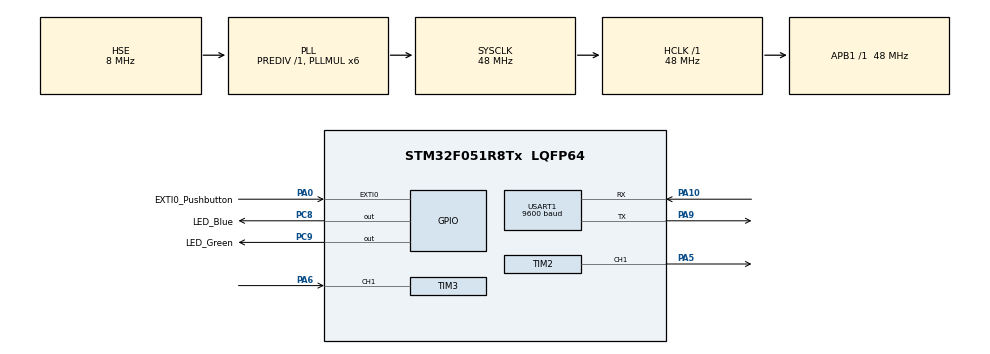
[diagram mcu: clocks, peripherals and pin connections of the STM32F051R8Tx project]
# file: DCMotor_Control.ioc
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Dma.Request0=USART1_TX
Dma.Request1=TIM2_CH1
Dma.TIM2_CH1.1.Direction=DMA_PERIPH_TO_MEMORY
Dma.TIM2_CH1.1.Instance=DMA1_Channel5
Dma.TIM2_CH1.1.MemDataAlignment=DMA_MDATAALIGN_WORD
Dma.TIM2_CH1.1.MemInc=DMA_MINC_ENABLE
Dma.TIM2_CH1.1.Mode=DMA_NORMAL
Dma.TIM2_CH1.1.PeriphDataAlignment=DMA_PDATAALIGN_WORD
Dma.TIM2_CH1.1.PeriphInc=DMA_PINC_DISABLE
Dma.TIM2_CH1.1.Priority=DMA_PRIORITY_LOW
Dma.USART1_TX.0.Direction=DMA_MEMORY_TO_PERIPH
Dma.USART1_TX.0.Instance=DMA1_Channel2
Dma.USART1_TX.0.MemDataAlignment=DMA_MDATAALIGN_BYTE
Dma.USART1_TX.0.MemInc=DMA_MINC_ENABLE
Dma.USART1_TX.0.Mode=DMA_NORMAL
Dma.USART1_TX.0.PeriphDataAlignment=DMA_PDATAALIGN_BYTE
Dma.USART1_TX.0.PeriphInc=DMA_PINC_DISABLE
Dma.USART1_TX.0.Priority=DMA_PRIORITY_LOW
Mcu.Family=STM32F0
Mcu.Name=STM32F051R8Tx
Mcu.Package=LQFP64
NVIC.DMA1_Channel2_3_IRQn=true\:0\:0\:false\:false\:true\:false\:true\:true
NVIC.DMA1_Channel4_5_IRQn=true\:0\:0\:false\:false\:true\:false\:true\:true
NVIC.EXTI0_1_IRQn=true\:0\:0\:false\:false\:true\:true\:true\:true
NVIC.TIM3_IRQn=true\:0\:0\:false\:false\:true\:true\:true\:true
NVIC.TIM6_DAC_IRQn=true\:0\:0\:false\:false\:true\:true\:true\:true
PA0.GPIO_Label=EXTI0_Pushbutton
PA0.Signal=GPXTI0
PA10.Mode=Asynchronous
PA10.Signal=USART1_RX
PA13.GPIO_Label=SWDIO
PA13.Mode=Serial_Wire
PA13.Signal=SYS_SWDIO
PA14.GPIO_Label=SWCLK
PA14.Mode=Serial_Wire
PA14.Signal=SYS_SWCLK
PA5.Signal=S_TIM2_CH1_ETR
PA6.Signal=S_TIM3_CH1
PA9.Mode=Asynchronous
PA9.Signal=USART1_TX
PC8.GPIO_Label=LED_Blue
PC8.Signal=GPIO_Output
PC9.GPIO_Label=LED_Green
PC9.Signal=GPIO_Output
PF0-OSC_IN.Mode=HSE-External-Oscillator
PF0-OSC_IN.Signal=RCC_OSC_IN
PF1-OSC_OUT.Mode=HSE-External-Oscillator
PF1-OSC_OUT.Signal=RCC_OSC_OUT
ProjectManager.HeapSize=0x200
ProjectManager.StackSize=0x400
ProjectManager.TargetToolchain=STM32CubeIDE
RCC.AHBFreq_Value=48000000
RCC.APB1Freq_Value=48000000
RCC.APB1TimFreq_Value=48000000
RCC.HCLKFreq_Value=48000000
RCC.PLLMUL=RCC_PLL_MUL6
RCC.PLLSourceVirtual=RCC_PLLSOURCE_HSE
RCC.SYSCLKFreq_VALUE=48000000
RCC.SYSCLKSource=RCC_SYSCLKSOURCE_PLLCLK
SH.S_TIM2_CH1_ETR.0=TIM2_CH1,PWM Generation1 CH1
SH.S_TIM3_CH1.0=TIM3_CH1,Input_Capture1_from_TI1
TIM2.Channel-PWM\ Generation1\ CH1=TIM_CHANNEL_1
TIM2.Period=100-1
TIM2.Prescaler=48-1
TIM3.AutoReloadPreload=TIM_AUTORELOAD_PRELOAD_DISABLE
TIM3.Channel-Input_Capture1_from_TI1=TIM_CHANNEL_1
TIM3.Period=0xFFFF
TIM3.Prescaler=48-1
TIM6.Period=100-1
TIM6.Prescaler=48000-1
USART1.BaudRate=9600
USART1.VirtualMode-Asynchronous=VM_ASYNC
VP_TIM2_VS_ClockSourceINT.Mode=Internal
VP_TIM3_VS_ClockSourceINT.Mode=Internal
VP_TIM6_VS_ClockSourceINT.Mode=Enable_Timer
board=STM32F0DISCOVERY

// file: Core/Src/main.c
/* USER CODE BEGIN Header */
/**
  ******************************************************************************
  * @file           : main.c
  * @brief          : Main program body
  ******************************************************************************
  * @attention
  *
  * Copyright (c) 2025 STMicroelectronics.
  * All rights reserved.
  *
  * This software is licensed under terms that can be found in the LICENSE file
  * in the root directory of this software component.
  * If no LICENSE file comes with this software, it is provided AS-IS.
  *
  ******************************************************************************
  */
/* USER CODE END Header */
#include "main.h"

TIM_HandleTypeDef htim2;
TIM_HandleTypeDef htim3;
TIM_HandleTypeDef htim6;
DMA_HandleTypeDef hdma_tim2_ch1;

UART_HandleTypeDef huart1;
DMA_HandleTypeDef hdma_usart1_tx;

void SystemClock_Config(void);
static void MX_GPIO_Init(void);
static void MX_DMA_Init(void);
static void MX_USART1_UART_Init(void);
static void MX_TIM6_Init(void);
static void MX_TIM2_Init(void);
static void MX_TIM3_Init(void);

int main(void)
{

  /* MCU Configuration--------------------------------------------------------*/

  /* Reset of all peripherals, Initializes the Flash interface and the Systick. */
  HAL_Init();

  /* Configure the system clock */
  SystemClock_Config();

  /* Initialize all configured peripherals */
  MX_GPIO_Init();
  MX_DMA_Init();
  MX_USART1_UART_Init();
  MX_TIM6_Init();
  MX_TIM2_Init();
  MX_TIM3_Init();
  /* USER CODE BEGIN 2 */
  app_entry();
  /* USER CODE END 2 */

  /* Infinite loop */
  while (1)
  {

  }
}

void SystemClock_Config(void)
{
  RCC_OscInitTypeDef RCC_OscInitStruct = {0};
  RCC_ClkInitTypeDef RCC_ClkInitStruct = {0};
  RCC_PeriphCLKInitTypeDef PeriphClkInit = {0};

  /** Initializes the RCC Oscillators according to the specified parameters
  * in the RCC_OscInitTypeDef structure.
  */
  RCC_OscInitStruct.OscillatorType = RCC_OSCILLATORTYPE_HSE;
  RCC_OscInitStruct.HSEState = RCC_HSE_ON;
  RCC_OscInitStruct.PLL.PLLState = RCC_PLL_ON;
  RCC_OscInitStruct.PLL.PLLSource = RCC_PLLSOURCE_HSE;
  RCC_OscInitStruct.PLL.PLLMUL = RCC_PLL_MUL6;
  RCC_OscInitStruct.PLL.PREDIV = RCC_PREDIV_DIV1;
  if (HAL_RCC_OscConfig(&RCC_OscInitStruct) != HAL_OK)
  {
    Error_Handler();
  }

  /** Initializes the CPU, AHB and APB buses clocks
  */
  RCC_ClkInitStruct.ClockType = RCC_CLOCKTYPE_HCLK|RCC_CLOCKTYPE_SYSCLK
                              |RCC_CLOCKTYPE_PCLK1;
  RCC_ClkInitStruct.SYSCLKSource = RCC_SYSCLKSOURCE_PLLCLK;
  RCC_ClkInitStruct.AHBCLKDivider = RCC_SYSCLK_DIV1;
  RCC_ClkInitStruct.APB1CLKDivider = RCC_HCLK_DIV1;

  if (HAL_RCC_ClockConfig(&RCC_ClkInitStruct, FLASH_LATENCY_1) != HAL_OK)
  {
    Error_Handler();
  }
  PeriphClkInit.PeriphClockSelection = RCC_PERIPHCLK_USART1;
  PeriphClkInit.Usart1ClockSelection = RCC_USART1CLKSOURCE_PCLK1;
  if (HAL_RCCEx_PeriphCLKConfig(&PeriphClkInit) != HAL_OK)
  {
    Error_Handler();
  }
}

static void MX_TIM2_Init(void)
{

  TIM_ClockConfigTypeDef sClockSourceConfig = {0};
  TIM_MasterConfigTypeDef sMasterConfig = {0};
  TIM_OC_InitTypeDef sConfigOC = {0};

  htim2.Instance = TIM2;
  htim2.Init.Prescaler = 48-1;
  htim2.Init.CounterMode = TIM_COUNTERMODE_UP;
  htim2.Init.Period = 100-1;
  htim2.Init.ClockDivision = TIM_CLOCKDIVISION_DIV1;
  htim2.Init.AutoReloadPreload = TIM_AUTORELOAD_PRELOAD_DISABLE;
  if (HAL_TIM_Base_Init(&htim2) != HAL_OK)
  {
    Error_Handler();
  }
  sClockSourceConfig.ClockSource = TIM_CLOCKSOURCE_INTERNAL;
  if (HAL_TIM_ConfigClockSource(&htim2, &sClockSourceConfig) != HAL_OK)
  {
    Error_Handler();
  }
  if (HAL_TIM_PWM_Init(&htim2) != HAL_OK)
  {
    Error_Handler();
  }
  sMasterConfig.MasterOutputTrigger = TIM_TRGO_RESET;
  sMasterConfig.MasterSlaveMode = TIM_MASTERSLAVEMODE_DISABLE;
  if (HAL_TIMEx_MasterConfigSynchronization(&htim2, &sMasterConfig) != HAL_OK)
  {
    Error_Handler();
  }
  sConfigOC.OCMode = TIM_OCMODE_PWM1;
  sConfigOC.Pulse = 0;
  sConfigOC.OCPolarity = TIM_OCPOLARITY_HIGH;
  sConfigOC.OCFastMode = TIM_OCFAST_DISABLE;
  if (HAL_TIM_PWM_ConfigChannel(&htim2, &sConfigOC, TIM_CHANNEL_1) != HAL_OK)
  {
    Error_Handler();
  }
  HAL_TIM_MspPostInit(&htim2);

}

static void MX_TIM3_Init(void)
{

  TIM_ClockConfigTypeDef sClockSourceConfig = {0};
  TIM_MasterConfigTypeDef sMasterConfig = {0};
  TIM_IC_InitTypeDef sConfigIC = {0};

  htim3.Instance = TIM3;
  htim3.Init.Prescaler = 48-1;
  htim3.Init.CounterMode = TIM_COUNTERMODE_UP;
  htim3.Init.Period = 0xFFFF;
  htim3.Init.ClockDivision = TIM_CLOCKDIVISION_DIV1;
  htim3.Init.AutoReloadPreload = TIM_AUTORELOAD_PRELOAD_DISABLE;
  if (HAL_TIM_Base_Init(&htim3) != HAL_OK)
  {
    Error_Handler();
  }
  sClockSourceConfig.ClockSource = TIM_CLOCKSOURCE_INTERNAL;
  if (HAL_TIM_ConfigClockSource(&htim3, &sClockSourceConfig) != HAL_OK)
  {
    Error_Handler();
  }
  if (HAL_TIM_IC_Init(&htim3) != HAL_OK)
  {
    Error_Handler();
  }
  sMasterConfig.MasterOutputTrigger = TIM_TRGO_RESET;
  sMasterConfig.MasterSlaveMode = TIM_MASTERSLAVEMODE_DISABLE;
  if (HAL_TIMEx_MasterConfigSynchronization(&htim3, &sMasterConfig) != HAL_OK)
  {
    Error_Handler();
  }
  sConfigIC.ICPolarity = TIM_INPUTCHANNELPOLARITY_RISING;
  sConfigIC.ICSelection = TIM_ICSELECTION_DIRECTTI;
  sConfigIC.ICPrescaler = TIM_ICPSC_DIV1;
  sConfigIC.ICFilter = 0;
  if (HAL_TIM_IC_ConfigChannel(&htim3, &sConfigIC, TIM_CHANNEL_1) != HAL_OK)
  {
    Error_Handler();
  }

}

static void MX_TIM6_Init(void)
{

  TIM_MasterConfigTypeDef sMasterConfig = {0};

  htim6.Instance = TIM6;
  htim6.Init.Prescaler = 48000-1;
  htim6.Init.CounterMode = TIM_COUNTERMODE_UP;
  htim6.Init.Period = 100-1;
  htim6.Init.AutoReloadPreload = TIM_AUTORELOAD_PRELOAD_DISABLE;
  if (HAL_TIM_Base_Init(&htim6) != HAL_OK)
  {
    Error_Handler();
  }
  sMasterConfig.MasterOutputTrigger = TIM_TRGO_RESET;
  sMasterConfig.MasterSlaveMode = TIM_MASTERSLAVEMODE_DISABLE;
  if (HAL_TIMEx_MasterConfigSynchronization(&htim6, &sMasterConfig) != HAL_OK)
  {
    Error_Handler();
  }

}

static void MX_USART1_UART_Init(void)
{

  huart1.Instance = USART1;
  huart1.Init.BaudRate = 9600;
  huart1.Init.WordLength = UART_WORDLENGTH_8B;
  huart1.Init.StopBits = UART_STOPBITS_1;
  huart1.Init.Parity = UART_PARITY_NONE;
  huart1.Init.Mode = UART_MODE_TX_RX;
  huart1.Init.HwFlowCtl = UART_HWCONTROL_NONE;
  huart1.Init.OverSampling = UART_OVERSAMPLING_16;
  huart1.Init.OneBitSampling = UART_ONE_BIT_SAMPLE_DISABLE;
  huart1.AdvancedInit.AdvFeatureInit = UART_ADVFEATURE_NO_INIT;
  if (HAL_UART_Init(&huart1) != HAL_OK)
  {
    Error_Handler();
  }

}

static void MX_DMA_Init(void)
{

  /* DMA controller clock enable */
  __HAL_RCC_DMA1_CLK_ENABLE();

  /* DMA interrupt init */
  /* DMA1_Channel2_3_IRQn interrupt configuration */
  HAL_NVIC_SetPriority(DMA1_Channel2_3_IRQn, 0, 0);
  HAL_NVIC_EnableIRQ(DMA1_Channel2_3_IRQn);
  /* DMA1_Channel4_5_IRQn interrupt configuration */
  HAL_NVIC_SetPriority(DMA1_Channel4_5_IRQn, 0, 0);
  HAL_NVIC_EnableIRQ(DMA1_Channel4_5_IRQn);

}

static void MX_GPIO_Init(void)
{
  GPIO_InitTypeDef GPIO_InitStruct = {0};

  /* GPIO Ports Clock Enable */
  __HAL_RCC_GPIOF_CLK_ENABLE();
  __HAL_RCC_GPIOA_CLK_ENABLE();
  __HAL_RCC_GPIOC_CLK_ENABLE();

  /*Configure GPIO pin Output Level */
  HAL_GPIO_WritePin(GPIOC, LED_Blue_Pin|LED_Green_Pin, GPIO_PIN_RESET);

  /*Configure GPIO pin : EXTI0_Pushbutton_Pin */
  GPIO_InitStruct.Pin = EXTI0_Pushbutton_Pin;
  GPIO_InitStruct.Mode = GPIO_MODE_IT_RISING;
  GPIO_InitStruct.Pull = GPIO_NOPULL;
  HAL_GPIO_Init(EXTI0_Pushbutton_GPIO_Port, &GPIO_InitStruct);

  /*Configure GPIO pins : LED_Blue_Pin LED_Green_Pin */
  GPIO_InitStruct.Pin = LED_Blue_Pin|LED_Green_Pin;
  GPIO_InitStruct.Mode = GPIO_MODE_OUTPUT_PP;
  GPIO_InitStruct.Pull = GPIO_NOPULL;
  GPIO_InitStruct.Speed = GPIO_SPEED_FREQ_LOW;
  HAL_GPIO_Init(GPIOC, &GPIO_InitStruct);

  /* EXTI interrupt init*/
  HAL_NVIC_SetPriority(EXTI0_1_IRQn, 0, 0);
  HAL_NVIC_EnableIRQ(EXTI0_1_IRQn);

}

void Error_Handler(void)
{
  __disable_irq();
  while (1)
  {
  }
}
